AUTOSAR XML (schema 4.0)
package /JLR_ECU_Package
  ecu instance EngineControlModule
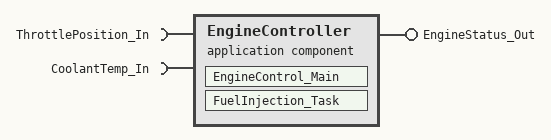
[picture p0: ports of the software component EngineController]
  application sw component type EngineController: category=APPLICATION
    provide port EngineStatus_Out
    require port ThrottlePosition_In
    require port CoolantTemp_In
    behavior EngineController_IB
      runnable EngineControl_Main: minimum-start-interval=0.01
      runnable FuelInjection_Task
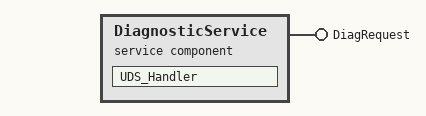
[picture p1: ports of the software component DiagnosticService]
  service sw component type DiagnosticService: category=SERVICE
    provide port DiagRequest
    behavior DiagService_IB
      runnable UDS_Handler
  can cluster VehicleCAN: baudrate=500000
